# f28p55x_clb_logic_control_regs register map
Vendor: Texas Instruments
Peripheral module from a debugger description file (folder C2000).
Address unit: 16 bits
Registers are 32-bit, read-write, no defined reset value unless marked. A register's access mark holds for its fields unless they carry their own. Offsets are as the file gives them; lines under a group give offsets from that group; [hi:lo] are bit positions; {n}, {i} and the like mark numbered series; 'fields as' and 'values as' point back to an identical list; <NAME> marks a mode.

## CLB_LOGIC_CONTROL_REGS — CLB LOGIC CONTROL Registers
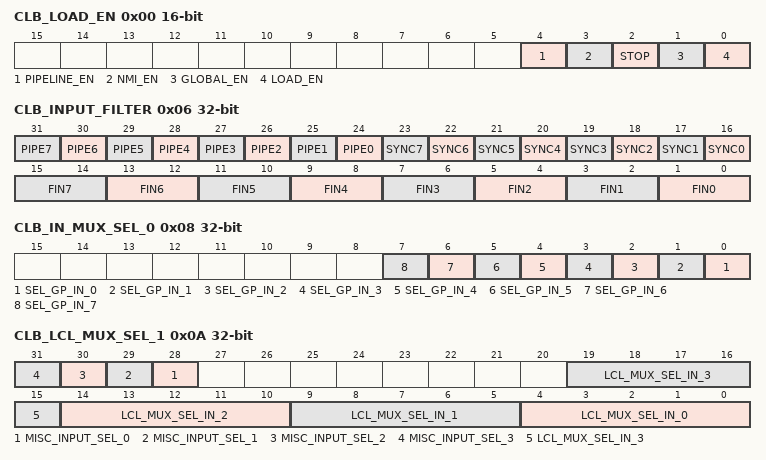
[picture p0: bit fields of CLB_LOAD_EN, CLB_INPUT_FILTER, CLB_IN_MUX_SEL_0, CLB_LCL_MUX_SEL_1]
0x00 CLB_LOAD_EN 16-bit — Global enable and indirect load enable control, only Global Enable Bit is LOCK protected
  [4] PIPELINE_EN — Enable input pipelining
  [3] NMI_EN — NMI output enable
  [2] STOP — Debug stop control
  [1] GLOBAL_EN — Global Enable
  [0] LOAD_EN — Load Enable
0x02 CLB_LOAD_ADDR — Indirect address
  [5:0] ADDR — Indirect Address
0x04 CLB_LOAD_DATA — Data for indirect loads
  [31:0] DATA — Data for indirect write
0x06 CLB_INPUT_FILTER — Input filter selection for both edge detection and synchronizers
  [n+24] PIPE{n} (n=0..7) — Enable pipeline {n}
  [n+16] SYNC{n} (n=0..7) — Synchronizer control {n}
  [2n+1:2n] FIN{n} (n=0..7) — Input filter control {n}
0x08 CLB_IN_MUX_SEL_0 — Input selection to decide between Signals and GP register
  [n] SEL_GP_IN_{n} (n=0..7) — Select GP register {n}
0x0A CLB_LCL_MUX_SEL_1 — Input Mux selection for local mux
  [n+28] MISC_INPUT_SEL_{n} (n=0..3) — Select MISC_INPUT
  [5n+4:5n] LCL_MUX_SEL_IN_{n} (n=0..3) — Local Mux select {n}
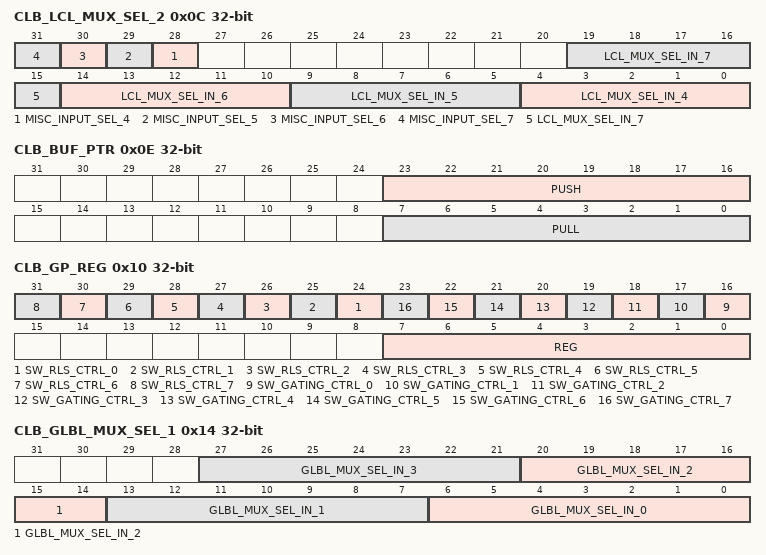
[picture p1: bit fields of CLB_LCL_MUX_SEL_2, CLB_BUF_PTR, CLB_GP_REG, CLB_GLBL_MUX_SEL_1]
0x0C CLB_LCL_MUX_SEL_2 — Input Mux selection for local mux
  [n+24] MISC_INPUT_SEL_{n} (n=4..7) — Select MISC_INPUT
  [5n-16:5n-20] LCL_MUX_SEL_IN_{n} (n=4..7) — Local Mux select {n}
0x0E CLB_BUF_PTR — PUSH and PULL pointers
  [23:16] PUSH — Data pointer for pull
  [7:0] PULL — Data pointer for pull
0x10 CLB_GP_REG — General purpose register for CELL inputs
  [n+24] SW_RLS_CTRL_{n} (n=0..7) — Software release control {n}
  [n+16] SW_GATING_CTRL_{n} (n=0..7) — Software gating control {n}
  [7:0] REG — General Purpose bit register
0x12 CLB_OUT_EN — CELL output enable register
  [31:0] OUTEN — CLB output enable
0x14 CLB_GLBL_MUX_SEL_1 — Global Mux select for CELL inputs
  [7n+6:7n] GLBL_MUX_SEL_IN_{n} (n=0..3) — Global Mux select {n}
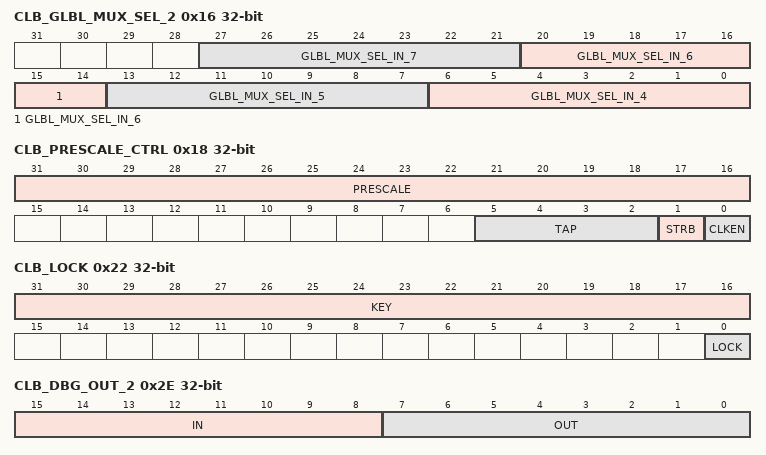
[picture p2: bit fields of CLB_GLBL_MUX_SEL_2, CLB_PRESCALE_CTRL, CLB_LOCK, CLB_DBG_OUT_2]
0x16 CLB_GLBL_MUX_SEL_2 — Global Mux select for CELL inputs
  [7n-22:7n-28] GLBL_MUX_SEL_IN_{n} (n=4..7) — Global Mux select {n}
0x18 CLB_PRESCALE_CTRL — Prescaler register control
  [31:16] PRESCALE — Value of prescale register
  [5:2] TAP — TAP Select value
  [1] STRB — Enable the Strobe mode of operation
  [0] CLKEN — Enable the prescale clock generator
0x20 CLB_INTR_TAG_REG 16-bit — Interrupt Tag register
  [5:0] TAG — Interrupt tag
0x22 CLB_LOCK — Lock control register
  [31:16] KEY — Key for enabling write
  [0] LOCK — LOCK enable
0x24 CLB_HLC_INSTR_READ_PTR 16-bit — HLC instruction read pointer
  [4:0] READ_PTR
0x26 CLB_HLC_INSTR_VALUE 16-bit ro — HLC instruction read value
  [11:0] INSTR — HLC instruction value
0x2E CLB_DBG_OUT_2 — Visibility for CLB inputs and final asynchronous outputs
  [15:8] IN — CLB CELL Inputs
  [7:0] OUT — Outputs of CLB Async block
{0x30+2i} CLB_DBG_R{i} ro (i=0..3) — R{i} of High level Controller
  [31:0] DBG — CLB_DBG_R{i}
{0x38+2i} CLB_DBG_C{i} ro (i=0..2) — Count of Unit {i}
  [31:0] DBG — CLB_DBG_C{i}
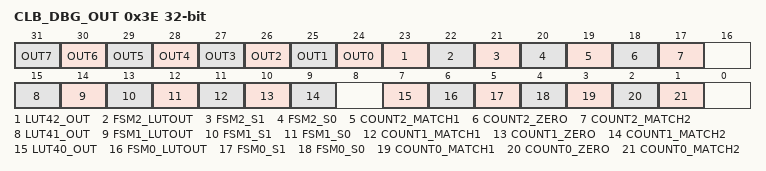
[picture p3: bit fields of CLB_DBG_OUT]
0x3E CLB_DBG_OUT ro — Outputs of various units in the Cell
  [n+24] OUT{n} (n=0..7) — CELL Output {n}
  [23] LUT42_OUT — LUT4_OUT UNIT 2
  [22] FSM2_LUTOUT — FSM_LUT_OUT UNIT 2
  [21] FSM2_S1 — FSM_S1 UNIT 2
  [20] FSM2_S0 — FSM_S0 UNIT 2
  [19] COUNT2_MATCH1 — COUNT_MATCH1 UNIT 2
  [18] COUNT2_ZERO — COUNT_ZERO UNIT 2
  [17] COUNT2_MATCH2 — COUNT_MATCH2 UNIT 2
  [15] LUT41_OUT — LUT4_OUT UNIT 1
  [14] FSM1_LUTOUT — FSM_LUT_OUT UNIT 1
  [13] FSM1_S1 — FSM_S1 UNIT 1
  [12] FSM1_S0 — FSM_S0 UNIT 1
  [11] COUNT1_MATCH1 — COUNT_MATCH1 UNIT 1
  [10] COUNT1_ZERO — COUNT_ZERO UNIT 1
  [9] COUNT1_MATCH2 — COUNT_MATCH2 UNIT 1
  [7] LUT40_OUT — LUT4_OUT UNIT 0
  [6] FSM0_LUTOUT — FSM_LUT_OUT UNIT 0
  [5] FSM0_S1 — FSM_S1 UNIT 0
  [4] FSM0_S0 — FSM_S0 UNIT 0
  [3] COUNT0_MATCH1 — COUNT_MATCH1 UNIT 0
  [2] COUNT0_ZERO — COUNT_ZERO UNIT 0
  [1] COUNT0_MATCH2 — COUNT_MATCH2 UNIT 0
